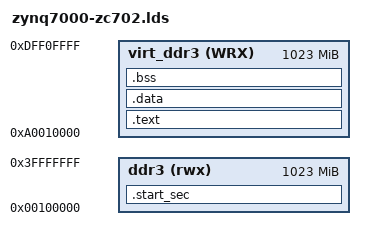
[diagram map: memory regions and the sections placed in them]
/*******************************************************************/
/*                                                                 */
/* This file is automatically generated by linker script generator.*/
/*                                                                 */
/* Version:                                 */
/*                                                                 */
/* Copyright (c) 2010 Xilinx, Inc.  All rights reserved.           */
/*                                                                 */
/* Description : Cortex-A9 Linker Script                          */
/*                                                                 */
/*******************************************************************/

/* Define Memories in the system */
BOOT_STACK_SIZE = 0x4000;
RAM_VECTORS_SIZE = 72;

/* Specify the memory areas */
MEMORY
{
    ddr3 (rwx)   			: ORIGIN = 0x00100000, LENGTH = 0x3FF00000
    virt_ddr3 (WRX)   		: ORIGIN = 0xA0010000, LENGTH = 0x3FF00000
}

/* Specify the default entry point to the program */

ENTRY(_boot_start)

/* Define the sections, and where they are mapped in memory */
SECTIONS
{
	. = ORIGIN(ddr3);
	. = ALIGN(4);

    _start_image_addr = .;

	.start_sec : {
		. = ALIGN(0x1000);

		/* read only area. */
		boot.o(.text)
		xil-crt0.o(.text .text.*)
		cpu_init.o(.text .text.*)
		bootmmu.o(.text .text.*)

		boot.o(.rodata .rodata.*)
		xil-crt0.o(.rodata .rodata.*)
		cpu_init.o(.rodata .rodata.*)
		bootmmu.o(.rodata .rodata.*)

		/* already initialized to zero. */
		boot.o(.data .data.*)
		xil-crt0.o(.data .data.*)
		cpu_init.o(.data .data.*)
		bootmmu.o(.data .data.*)

		/* initialization start checkpoint. */
		PROVIDE(boot_start_addr = .);

		boot.o(.bss .bss.* COMMON)
		xil-crt0.o(.bss .bss.* COMMON)
		cpu_init.o(.bss .bss.* COMMON)
		bootmmu.o(.bss .bss.* COMMON)

		/* stack for booting code. */
		. = ALIGN(0x1000);
		PROVIDE(stacks_start = .);
		. += BOOT_STACK_SIZE;
		PROVIDE(stacks_end = .);
		PROVIDE(stacks_top = .);

		/* initialization end checkpoint. */
		PROVIDE(boot_end_addr = .);
	} > ddr3

	.text : AT(0x00110000) {
		*(.vectors)
		. = ALIGN(0x1000);
		*(.text .text.* .gnu.linkonce.t.*)
	} > virt_ddr3

	. = ALIGN(0x1000);
	/* Other Kernel code text checkpoint. */
	PROVIDE(kern_text = .);

	.data : {
		*(.data .data.*)
		/* user app */
		. = ALIGN(0x1000);
		PROVIDE(_binary_fs_img_start = .);
		*(.rawdata_fs_img*)
		PROVIDE(_binary_fs_img_end = .);
		PROVIDE(_binary_init_start = .);
		*(.rawdata_init*)
		PROVIDE(_binary_init_end = .);
		PROVIDE(_binary_default_fs_start = .);
		*(.rawdata_memfs*)
		PROVIDE(_binary_default_fs_end = .);
	} > virt_ddr3 

	PROVIDE(kernel_data_begin = .);

	_image_size = . - 0xA0000000;

	.bss : {
		PROVIDE(__bss_start__ = .);
		*(.bss .bss.* COMMON)
		PROVIDE(__bss_end__ = .);
	} > virt_ddr3
	. = ALIGN(0x1000);
	PROVIDE(kernel_data_end = .);
}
